VERSION ""

NS_ :

BS_:

BU_: + XXX 0

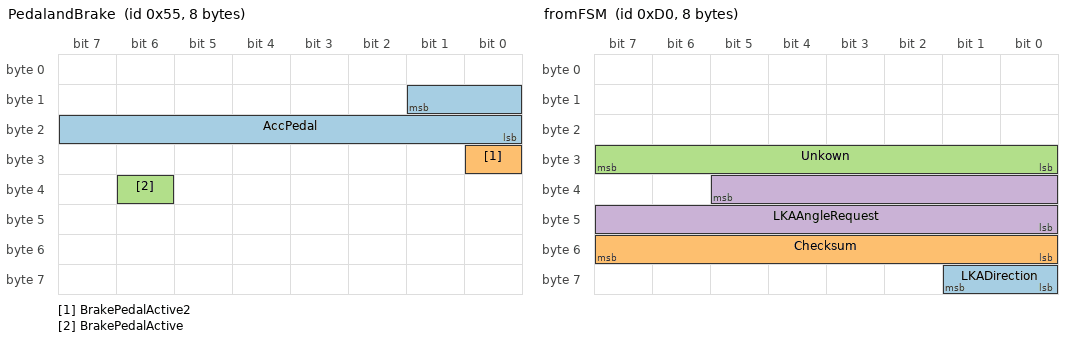
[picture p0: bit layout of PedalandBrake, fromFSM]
BO_ 85 PedalandBrake: 8 XXX
 SG_ AccPedal : 9|10@0+ (0.1,0) [0|1023] "" XXX
 SG_ BrakePedalActive2 : 24|1@0+ (1,0) [0|1] "" XXX
 SG_ BrakePedalActive : 38|1@0+ (1,0) [0|1] "" XXX

BO_ 8 SteeringAngle: 8 XXX
 SG_ SteeringDirection : 42|1@0+ (1,0) [0|1] "" XXX
 SG_ SteeringAngle : 53|14@0+ (0.04,0) [0|65535] "degrees" XXX

BO_ 101 EngineInfo: 8 XXX
 SG_ EngineSpeed : 52|13@0+ (1,0) [0|1023] "" XXX

BO_ 336 VehicleSpeed: 8 XXX
 SG_ VehicleSpeed : 55|16@0+ (0.01,0) [0|2047] "" XXX

BO_ 192 Gear: 8 XXX
 SG_ TransmissionGear : 36|3@0+ (1,1) [0|7] "" XXX

BO_ 652 untitled: 8 XXX

BO_ 681 MiscCarInfo: 8 XXX
 SG_ TurnSignal : 0|2@1+ (1,0) [0|3] "" XXX
 SG_ HighBeamOn : 52|1@0+ (1,0) [0|1] "" XXX

BO_ 304 VehicleSpeed: 8 XXX
 SG_ VehicleSpeed : 31|16@0+ (0.01,0) [0|65535] "km/h" XXX

BO_ 48 fromFSM: 8 XXX

BO_ 208 fromFSM: 8 XXX
 SG_ LKADirection : 56|2@1+ (1,0) [0|3] "" XXX
 SG_ Checksum : 48|8@1+ (1,0) [0|255] "" XXX
 SG_ Unkown : 24|8@1+ (1,0) [0|255] "" XXX
 SG_ LKAAngleRequest : 37|14@0+ (0.04,-327.68) [0|32774] "degrees" XXX

BO_ 352 fromFSM: 8 XXX

BO_ 624 fromFSM: 8 XXX

BO_ 640 fromFSM: 8 XXX
 SG_ SpeedTarget : 40|8@1+ (1,0) [0|255] "" XXX

BO_ 853 fromFSM: 8 XXX

BO_ 709 fromECM: 8 XXX
 SG_ SpeedTargetACC : 0|9@0+ (0.5,0) [0|511] "" XXX

BO_ 880 fromECM: 8 XXX

BO_ 293 fromServo: 8 XXX
 SG_ SteeringAngle : 47|16@0+ (0.04,-32768) [0|65535] "deg" XXX

BO_ 224 fromServo: 8 XXX

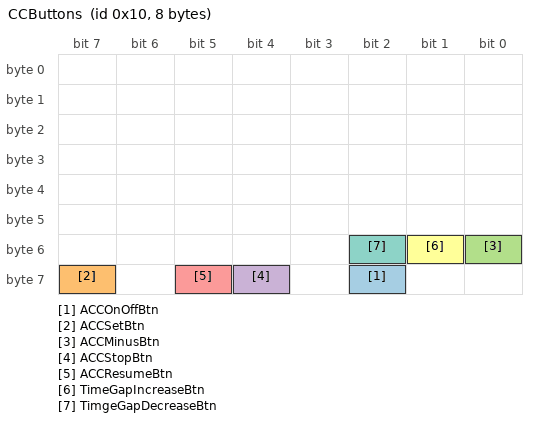
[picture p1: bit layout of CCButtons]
BO_ 16 CCButtons: 8 XXX
 SG_ ACCOnOffBtn : 58|1@0+ (1,0) [0|1] "" XXX
 SG_ ACCSetBtn : 63|1@0+ (1,0) [0|1] "" XXX
 SG_ ACCMinusBtn : 48|1@0+ (1,0) [0|1] "" XXX
 SG_ ACCStopBtn : 60|1@0+ (1,0) [0|1] "" XXX
 SG_ ACCResumeBtn : 61|1@0+ (1,0) [0|1] "" XXX
 SG_ TimeGapIncreaseBtn : 49|1@0+ (1,0) [0|1] "" XXX
 SG_ TimgeGapDecreaseBtn : 50|1@0+ (1,0) [0|1] "" XXX

CM_ SG_ 85 BrakePedalActive2 "Active during braking";
CM_ SG_ 85 BrakePedalActive "Brake pedal pushed";
CM_ SG_ 8 SteeringDirection "1=Right turn, 0=Left turn";
CM_ SG_ 192 TransmissionGear "0 = 1st gear, 1= 2nd gear... Onlyh activated in tip-mode";
CM_ SG_ 681 TurnSignal "0 = Nothing, 1= Left, 3=Right";
CM_ SG_ 681 HighBeamOn "1=HighBeam On, 0=HighBeam Off";
CM_ SG_ 208 LKADirection "0 = No lka active, 1=LKA steer right, 2=LKA steer left";
CM_ SG_ 208 Checksum "Checksum calculated as a one-complement addition of LKAAngleRequest+LKADirection+Unkown, Zeros used to pad missing bits.";
CM_ SG_ 208 Unkown "Used in checksum calculation";
CM_ SG_ 208 LKAAngleRequest "+ = right, - = left";
CM_ SG_ 640 SpeedTarget "SpeedTarget ACC (noisy bf starting acc Jumps from 0->252->0)";
CM_ SG_ 709 SpeedTargetACC "SpeedTargetACC";
CM_ SG_ 293 SteeringAngle "Correlates with steering angle.";
CM_ SG_ 16 ACCOnOffBtn "Cruise control on/off button pressed";
CM_ SG_ 16 ACCSetBtn "Acc Set button (+) pressed";
CM_ SG_ 16 ACCMinusBtn "ACC Minus (-) button pressed";
CM_ SG_ 16 ACCStopBtn "ACC Stop button pressed";
CM_ SG_ 16 ACCResumeBtn "ACC Resume button pressed";
CM_ SG_ 16 TimeGapIncreaseBtn "Increase the time gap on ACC";
CM_ SG_ 16 TimgeGapDecreaseBtn "Decrease the time gap on ACC";
